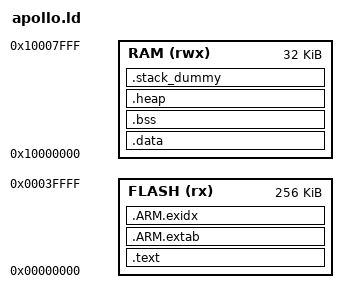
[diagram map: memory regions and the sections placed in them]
/*************************************************************************************************/
/*!
 *  \file
 *
 *  \brief  Linker script describing the memory layout for the Ambiq Brazo platform.
 *
 *  $Date: 2015-03-31 06:44:57 -0700 (Tue, 31 Mar 2015) $
 *  $Revision: 2625 $
 *
 *  Copyright (c) 2013 Wicentric, Inc., all rights reserved.
 *  Wicentric confidential and proprietary.
 *
 *  IMPORTANT.  Your use of this file is governed by a Software License Agreement
 *  ("Agreement") that must be accepted in order to download or otherwise receive a
 *  copy of this file.  You may not use or copy this file for any purpose other than
 *  as described in the Agreement.  If you do not agree to all of the terms of the
 *  Agreement do not use this file and delete all copies in your possession or control;
 *  if you do not have a copy of the Agreement, you must contact Wicentric, Inc. prior
 *  to any use, copying or further distribution of this software.
 */
/*************************************************************************************************/

OUTPUT_FORMAT ("elf32-littlearm", "elf32-bigarm", "elf32-littlearm")
ENTRY(Reset_Handler)
SEARCH_DIR(.)

MEMORY
{
  FLASH (rx) : ORIGIN = 0x00000000, LENGTH = 0x00040000   /* 256K */
  RAM  (rwx) : ORIGIN = 0x10000000, LENGTH = 0x00008000   /*  32K */
}

/* Following linker definitions are availabe for use by applicaiton software.
 *   __exidx_start
 *   __exidx_end
 *   __etext
 *   __data_start__
 *   __preinit_array_start
 *   __preinit_array_end
 *   __init_array_start
 *   __init_array_end
 *   __fini_array_start
 *   __fini_array_end
 *   __data_end__
 *   __bss_start__
 *   __bss_end__
 *   __end__
 *   end
 *   __HeapLimit
 *   __StackLimit
 *   __StackTop
 *   __stack
 */

SECTIONS
{
  .text :
  {
    KEEP(*(.isr_vector))
    *(.text*)

    KEEP(*(.init))
    KEEP(*(.fini))

    /* .ctors */
    *crtbegin.o(.ctors)
    *crtbegin?.o(.ctors)
    *(EXCLUDE_FILE(*crtend?.o *crtend.o) .ctors)
    *(SORT(.ctors.*))
    *(.ctors)

    /* .dtors */
    *crtbegin.o(.dtors)
    *crtbegin?.o(.dtors)
    *(EXCLUDE_FILE(*crtend?.o *crtend.o) .dtors)
    *(SORT(.dtors.*))
    *(.dtors)

    *(.rodata*)

    KEEP(*(.eh_frame*))
  } > FLASH

  .ARM.extab :
  {
    *(.ARM.extab* .gnu.linkonce.armextab.*)
  } > FLASH

  __exidx_start = .;
  .ARM.exidx :
  {
    *(.ARM.exidx* .gnu.linkonce.armexidx.*)
  } > FLASH
  __exidx_end = .;

  __etext = .;

  .data : AT (__etext)
  {
    __data_start__ = .;
    *(vtable)
    *(.data*)

    . = ALIGN(4);
    /* preinit data */
    PROVIDE_HIDDEN (__preinit_array_start = .);
    KEEP(*(.preinit_array))
    PROVIDE_HIDDEN (__preinit_array_end = .);

    . = ALIGN(4);
    /* init data */
    PROVIDE_HIDDEN (__init_array_start = .);
    KEEP(*(SORT(.init_array.*)))
    KEEP(*(.init_array))
    PROVIDE_HIDDEN (__init_array_end = .);


    . = ALIGN(4);
    /* finit data */
    PROVIDE_HIDDEN (__fini_array_start = .);
    KEEP(*(SORT(.fini_array.*)))
    KEEP(*(.fini_array))
    PROVIDE_HIDDEN (__fini_array_end = .);

    KEEP(*(.jcr*))
    . = ALIGN(4);
    /* All data end */
    __data_end__ = .;

  } > RAM

  .bss :
  {
    . = ALIGN(4);
    __bss_start__ = .;
    *(.bss*)
    *(COMMON)
    . = ALIGN(4);
    __bss_end__ = .;
  } > RAM

  .heap (COPY):
  {
    __end__ = .;
    end = __end__;
    *(.heap*)
    __HeapLimit = .;
  } > RAM

  /* .stack_dummy section doesn't contains any symbols. It is only
   * used for linker to calculate size of stack sections, and assign
   * values to stack symbols later */
  .stack_dummy (COPY):
  {
    *(.stack*)
  } > RAM

  /* Set stack top to end of RAM, and stack limit move down by
   * size of stack_dummy section */
  __StackTop = ORIGIN(RAM) + LENGTH(RAM);
  __StackLimit = __StackTop - SIZEOF(.stack_dummy);
  PROVIDE(__stack = __StackTop);

  /* Check if data + heap + stack exceeds RAM limit */
  ASSERT(__StackLimit >= __HeapLimit, "region RAM overflowed with stack")

  /* DWARF debug sections. */
  .debug_info     0 : { *(.debug_info .gnu.linkonce.wi.*) }
  .debug_abbrev   0 : { *(.debug_abbrev) }
  .debug_line     0 : { *(.debug_line) }
  .debug_frame    0 : { *(.debug_frame) }
  .debug_str      0 : { *(.debug_str) }
  .debug_loc      0 : { *(.debug_loc) }
  .debug_macinfo  0 : { *(.debug_macinfo) }
  .debug_ranges   0 : { *(.debug_ranges) }
}
